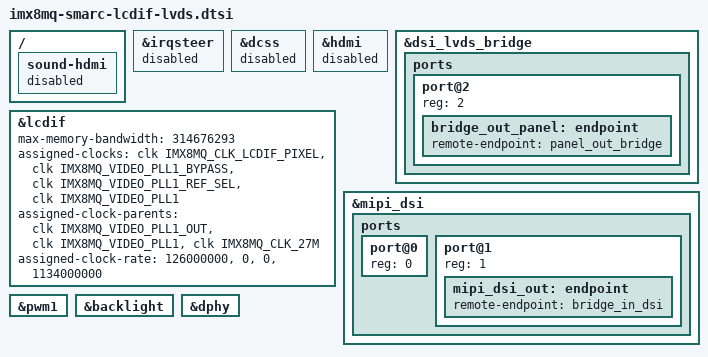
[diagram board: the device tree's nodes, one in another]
// SPDX-License-Identifier: (GPL-2.0 OR MIT)
/*
 * Copyright 2017 NXP
 * Copyright 2024 Embedian, Inc.
 * Copyright (C) 2017-2018 Pengutronix, Lucas Stach <kernel@pengutronix.de>
 */

/ {
	sound-hdmi {
		status = "disabled";
	};
};

#include "imx8mq-smarc-lvds-panel.dtsi"

&irqsteer {
	status = "disabled";
};

&dcss {
	status = "disabled";
};

&hdmi {
	status = "disabled";
};

&dsi_lvds_bridge {
	status = "okay";

	ports {
		#address-cells = <1>;
		#size-cells = <0>;

		port@2 {
			reg = <2>;
			bridge_out_panel: endpoint {
				remote-endpoint = <&panel_out_bridge>;
			};
		};
	};
};

&lcdif {
	status = "okay";
	max-memory-bandwidth = <314676293>; /* 1280x1024-32@60 */

	assigned-clocks = <&clk IMX8MQ_CLK_LCDIF_PIXEL>,
			<&clk IMX8MQ_VIDEO_PLL1_BYPASS>,
			<&clk IMX8MQ_VIDEO_PLL1_REF_SEL>,
			<&clk IMX8MQ_VIDEO_PLL1>;
	assigned-clock-parents = <&clk IMX8MQ_VIDEO_PLL1_OUT>,
			<&clk IMX8MQ_VIDEO_PLL1>,
			<&clk IMX8MQ_CLK_27M>;
	assigned-clock-rate = <126000000>, <0>, <0>, <1134000000>;
};

&mipi_dsi {
	status = "okay";

	ports {
		#address-cells = <1>;
		#size-cells = <0>;
		/* DCSS Port (IN) */
		port@0 {
			reg = <0>;
		};
		/* MIPI DSI Port (OUT)*/
		port@1 {
			reg = <1>;
			mipi_dsi_out: endpoint {
				remote-endpoint = <&bridge_in_dsi>;
			};
		};
	};
};

&pwm1 {
	status = "okay";
};

&backlight {
	status = "okay";
};

&dphy {
	status = "okay";
};
